# netx90_app register map
File version: 1.0
CPU: CM4 r0p1, little endian, MPU, FPU, 4 interrupt priority bits, 78 interrupts
Registers are 32-bit, read-write, reset 0x0 unless marked. A register's access mark holds for its fields unless they carry their own. Offsets are from the block's base; [hi:lo] are bit positions; {n}, {i} and the like mark numbered series.

## hash_ctx_md5
Base 0xFF080200
0x00 hash_ctx_md5_a — MD5 context register a
  [31:0] val — Register a value
0x04 hash_ctx_md5_b — MD5 context register b
  [31:0] val — Register b value
0x08 hash_ctx_md5_c — MD5 context register c
  [31:0] val — Register c value
0x0C hash_ctx_md5_d — MD5 context register d
  [31:0] val — Register d value
0x10 hash_ctx_md5_ar — MD5 context register ar
  [31:0] val — Register ar value
0x14 hash_ctx_md5_br — MD5 context register br
  [31:0] val — Register br value
0x18 hash_ctx_md5_cr — MD5 context register cr
  [31:0] val — Register cr value
0x1C hash_ctx_md5_dr — MD5 context register dr
  [31:0] val — Register dr value

## random
Base 0xFF080340
0x00 random_init reset 0x55555555 — Random initialization value: Write a value depending on Chip ID to this register to generate a random sequence different for each netX.
  [31:0] val — random init value
0x04 random_random ro — Random value: This random value sequence is derived from many random events inside netX chip.
  [31:0] val — random value

## ahb_abort — abort
Base 0xFF4016C0
0x00 abort_base reset not defined — Start-address of abort generating address area. Area size: 16Bytes Abort (AHB: HRESP=ERROR) will be generated by access to this area. Write access will be ignored. Read access returns 0xdeadbeef.
  [31:0] bf_align0 — bitField alignment value for aeabi compatibility
0x0C abort_end reset not defined — End-address of abort generating address area.
  [31:0] bf_align0 — bitField alignment value for aeabi compatibility

## sample_at_porn_stat
Base 0xFF4016D0
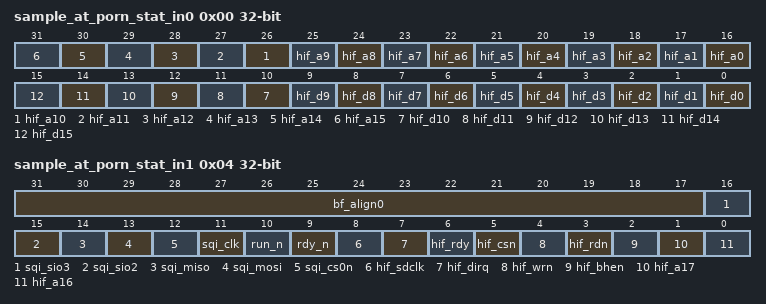
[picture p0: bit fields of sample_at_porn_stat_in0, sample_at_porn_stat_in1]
0x00 sample_at_porn_stat_in0 ro — Status of inputs sampled at power-on-reset (PORn) register 0. This register shows the status of the inputs sampled at power-on-reset. It will not change on normal system reset.
  [n+16] hif_a{n} (n=0..15) — Input status of pin 'hif_a{n}' sampled at power-on-reset
  [n] hif_d{n} (n=0..15) — Input status of pin 'hif_d{n}' sampled at power-on-reset
0x04 sample_at_porn_stat_in1 ro (reset mask 0x1FFFF) — Status of inputs sampled at power-on-reset (PORn) register 1. This register shows the status of the inputs sampled at power-on-reset. It will not change on normal system reset.
  [31:17] bf_align0 — bitField alignment value for aeabi compatibility
  [16] sqi_sio3 — Input status of pin 'sqi_sio3' sampled at power-on-reset
  [15] sqi_sio2 — Input status of pin 'sqi_sio2' sampled at power-on-reset
  [14] sqi_miso — Input status of pin 'sqi_miso' sampled at power-on-reset
  [13] sqi_mosi — Input status of pin 'sqi_mosi' sampled at power-on-reset
  [12] sqi_cs0n — Input status of pin 'sqi_cs0n' sampled at power-on-reset
  [11] sqi_clk — Input status of pin 'sqi_clk' sampled at power-on-reset
  [10] run_n — Input status of pin 'run_n' sampled at power-on-reset
  [9] rdy_n — Input status of pin 'rdy_n' sampled at power-on-reset
  [8] hif_sdclk — Input status of pin 'hif_sdclk' sampled at power-on-reset
  [7] hif_dirq — Input status of pin 'hif_dirq' sampled at power-on-reset
  [6] hif_rdy — Input status of pin 'hif_rdy' sampled at power-on-reset
  [5] hif_csn — Input status of pin 'hif_csn' sampled at power-on-reset
  [4] hif_wrn — Input status of pin 'hif_wrn' sampled at power-on-reset
  [3] hif_rdn — Input status of pin 'hif_rdn' sampled at power-on-reset
  [2] hif_bhen — Input status of pin 'hif_bhen' sampled at power-on-reset
  [1] hif_a17 — Input status of pin 'hif_a17' sampled at power-on-reset
  [0] hif_a16 — Input status of pin 'hif_a16' sampled at power-on-reset

## ecc_ctrl
Base 0xFF401780
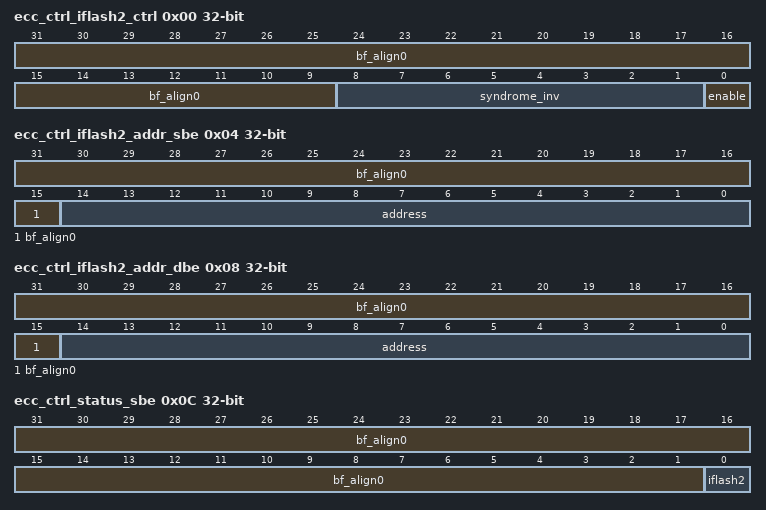
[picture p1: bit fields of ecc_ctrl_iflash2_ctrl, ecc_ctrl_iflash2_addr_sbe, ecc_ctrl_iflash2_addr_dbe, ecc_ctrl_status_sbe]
0x00 ecc_ctrl_iflash2_ctrl (reset mask 0x1FF) — IFLASH2 syndrome manipulation register
  [31:9] bf_align0 — bitField alignment value for aeabi compatibility
  [8:1] syndrome_inv — Inverts syndrome bits for ECC testing
  [0] enable — enable ECC
0x04 ecc_ctrl_iflash2_addr_sbe ro (reset mask 0x7FFF) — RAM Address of ECC single bit error (SBE): This register logs the RAM address where first ECC SBE occured. This first SBE address will be stored (even in case of further SBEs) until the appropriate bit in status_sbe register was cleared. Note1: Not all RAM ECCs support error address logging, e.g. dual-port RAMs Note2: This is the real RAM address, i.e. a 32-bit address except at xMAC 64-bit RAMs or RAMs that are not directly accessible by CPU.
  [31:15] bf_align0 — bitField alignment value for aeabi compatibility
  [14:0] address — Address of last ECC single bit error
0x08 ecc_ctrl_iflash2_addr_dbe ro (reset mask 0x7FFF) — RAM Address of ECC single bit error (DBE): This register logs the RAM address where first ECC DBE occured. This first DBE address will be stored (even in case of further DBEs) until the appropriate bit in status_sbe register was cleared. Note1: Not all RAM ECCs support error address logging, e.g. dual-port RAMs Note2: This is the real RAM address, i.e. a 32-bit address except at xMAC 64-bit RAMs or RAMs that are not directly accessible by CPU.
  [31:15] bf_align0 — bitField alignment value for aeabi compatibility
  [14:0] address — Address of last ECC double bit error
0x0C ecc_ctrl_status_sbe (reset mask 0x1) — ECC status SBE: This register collects single bit error (SBE) status information. In case of ECC SBE, a bit in this register will be set. Bits can be reset by writing '1' to the apprpriate bit position (write to clear). If a SBE or DBE bit is set, IRQ signal will be asserted. Note: No mask register is required, as error correction can be enabled for each RAM separately.
  [31:1] bf_align0 — bitField alignment value for aeabi compatibility
  [0] iflash2 — IFLASH2 Single Bit Error occured
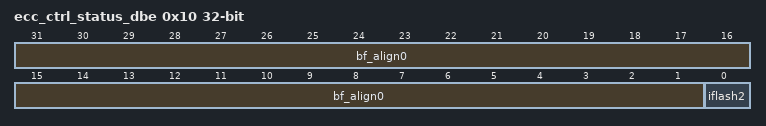
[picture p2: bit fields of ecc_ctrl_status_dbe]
0x10 ecc_ctrl_status_dbe (reset mask 0x1) — ECC status DBE: This register collects double bit error (DBE) status information. In case of ECC DBE, a bit of the appropriate RAM in this register will be set. Bits can be reset by writing '1' to the apprpriate bit position (write to clear). If a SBE or DBE bit is set, IRQ signal will be asserted. Note: No mask register is required, as error correction can be enabled for each RAM separately.
  [31:1] bf_align0 — bitField alignment value for aeabi compatibility
  [0] iflash2 — IFLASH2 Double Bit Error occured
